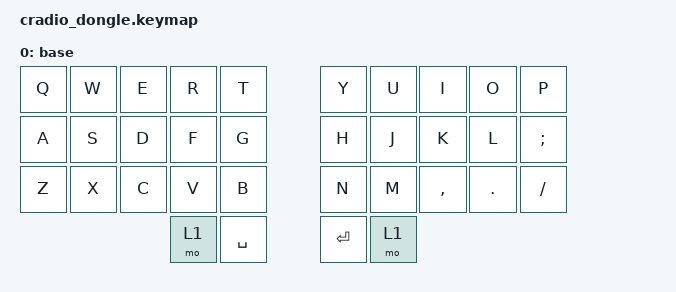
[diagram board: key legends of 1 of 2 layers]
#include <behaviors.dtsi>
#include <dt-bindings/zmk/keys.h>
#include <dt-bindings/zmk/bt.h>

/ {
  keymap {
    compatible = "zmk,keymap";

    base {
      bindings = <
        &kp Q &kp W &kp E &kp R &kp T      &kp Y &kp U &kp I &kp O &kp P
        &kp A &kp S &kp D &kp F &kp G      &kp H &kp J &kp K &kp L &kp SEMI
        &kp Z &kp X &kp C &kp V &kp B      &kp N &kp M &kp COMMA &kp DOT &kp SLASH
                    &mo 1 &kp SPACE      &kp ENTER &mo 1
      >;
    };

    bt {
      bindings = <
        &bt BT_PRV &bt BT_NXT &bt BT_CLR &bt BT_SEL 0 &trans
        &trans &trans &trans &trans &trans
        &trans &trans &trans &trans &trans
                    &trans &trans      &trans &trans
      >;
    };
  };
};
